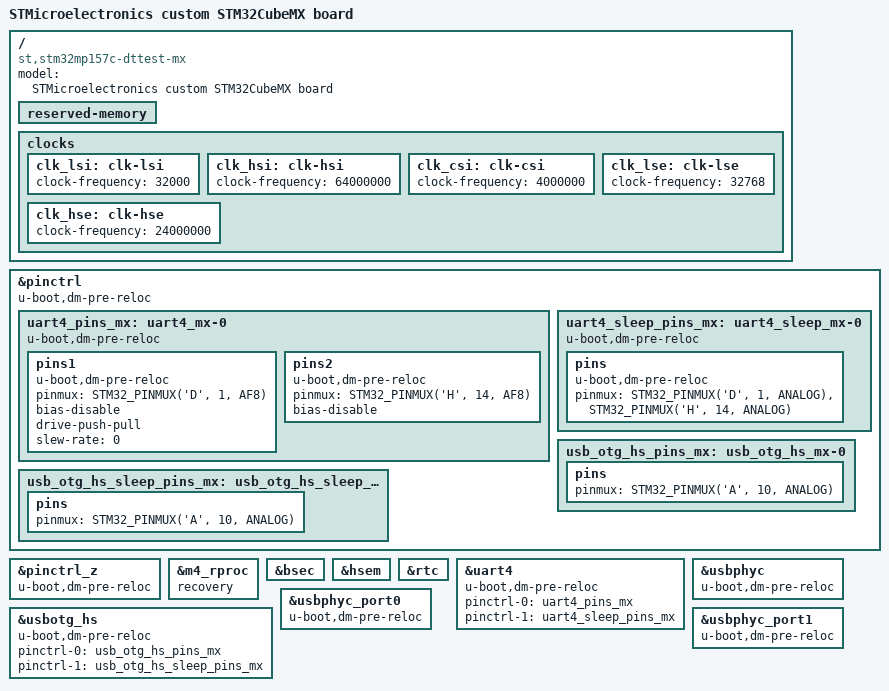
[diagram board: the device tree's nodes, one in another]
/* SPDX-License-Identifier: (GPL-2.0+ OR BSD-3-Clause) */
/*
 * Copyright (C) STMicroelectronics 2020 - All Rights Reserved
 * Author: STM32CubeMX code generation for STMicroelectronics.
 */

/* For more information on Device Tree configuration, please refer to
 * https://wiki.st.com/stm32mpu/wiki/Category:Device_tree_configuration
 */

/dts-v1/;
#include "stm32mp157c.dtsi"
#include "stm32mp157c-m4-srm.dtsi"
#include "stm32mp157caa-pinctrl.dtsi"

/* USER CODE BEGIN includes */
/* USER CODE END includes */

/ {
	model = "STMicroelectronics custom STM32CubeMX board";
	compatible = "st,stm32mp157c-dttest-mx", "st,stm32mp157";

	/* !!! log : Warning - no DDR config found: 'memory' node not generated  !!! */

	/*
	memory@??? {
		reg = < ??? >;
	};
	*/

	reserved-memory {
		#address-cells = <1>;
		#size-cells = <1>;
		ranges;

		/* USER CODE BEGIN reserved-memory */
		/* USER CODE END reserved-memory */

		/* !!! log : Warning - no DDR config found: 'gpu_reserved' node not generated  !!! */

		/*
		gpu_reserved: gpu@??? {
			reg = <??? ???}>;
			no-map;
		};
		*/
	};

	/* USER CODE BEGIN root */
	/* USER CODE END root */

	clocks {
		/* USER CODE BEGIN clocks */
		/* USER CODE END clocks */

		clk_lsi: clk-lsi {
			clock-frequency = <32000>;
		};

		clk_hsi: clk-hsi {
			clock-frequency = <64000000>;
		};

		clk_csi: clk-csi {
			clock-frequency = <4000000>;
		};

		clk_lse: clk-lse {
			clock-frequency = <32768>;
		};

		clk_hse: clk-hse {
			clock-frequency = <24000000>;
		};
	};

}; /*root*/

&pinctrl {
	u-boot,dm-pre-reloc;

	uart4_pins_mx: uart4_mx-0 {
		u-boot,dm-pre-reloc;
		pins1 {
			u-boot,dm-pre-reloc;
			pinmux = <STM32_PINMUX('D', 1, AF8)>; /* UART4_TX */
			bias-disable;
			drive-push-pull;
			slew-rate = <0>;
		};
		pins2 {
			u-boot,dm-pre-reloc;
			pinmux = <STM32_PINMUX('H', 14, AF8)>; /* UART4_RX */
			bias-disable;
		};
	};

	uart4_sleep_pins_mx: uart4_sleep_mx-0 {
		u-boot,dm-pre-reloc;
		pins {
			u-boot,dm-pre-reloc;
			pinmux = <STM32_PINMUX('D', 1, ANALOG)>, /* UART4_TX */
					 <STM32_PINMUX('H', 14, ANALOG)>; /* UART4_RX */
		};
	};

	usb_otg_hs_pins_mx: usb_otg_hs_mx-0 {
		pins {
			pinmux = <STM32_PINMUX('A', 10, ANALOG)>; /* USB_OTG_HS_ID */
		};
	};

	usb_otg_hs_sleep_pins_mx: usb_otg_hs_sleep_mx-0 {
		pins {
			pinmux = <STM32_PINMUX('A', 10, ANALOG)>; /* USB_OTG_HS_ID */
		};
	};

	/* USER CODE BEGIN pinctrl */
	/* USER CODE END pinctrl */
};

&pinctrl_z {
	u-boot,dm-pre-reloc;

	/* USER CODE BEGIN pinctrl_z */
	/* USER CODE END pinctrl_z */
};

&m4_rproc{
	recovery;
	status = "okay";

	/* USER CODE BEGIN m4_rproc */
	/* USER CODE END m4_rproc */
};

&bsec{
	status = "okay";

	/* USER CODE BEGIN bsec */
	/* USER CODE END bsec */
};

&hsem{
	status = "okay";

	/* USER CODE BEGIN hsem */
	/* USER CODE END hsem */
};

&rtc{
	status = "okay";

	/* USER CODE BEGIN rtc */
	/* USER CODE END rtc */
};

&uart4{
	u-boot,dm-pre-reloc;
	pinctrl-names = "default", "sleep";
	pinctrl-0 = <&uart4_pins_mx>;
	pinctrl-1 = <&uart4_sleep_pins_mx>;
	status = "okay";

	/* USER CODE BEGIN uart4 */
	/* USER CODE END uart4 */
};

&usbotg_hs{
	u-boot,dm-pre-reloc;
	pinctrl-names = "default", "sleep";
	pinctrl-0 = <&usb_otg_hs_pins_mx>;
	pinctrl-1 = <&usb_otg_hs_sleep_pins_mx>;
	status = "okay";

	/* USER CODE BEGIN usbotg_hs */
	/* USER CODE END usbotg_hs */
};

&usbphyc{
	u-boot,dm-pre-reloc;
	status = "okay";

	/* USER CODE BEGIN usbphyc */
	/* USER CODE END usbphyc */
};

&usbphyc_port0{
	u-boot,dm-pre-reloc;
	status = "okay";

	/* USER CODE BEGIN usbphyc_port0 */
	/* USER CODE END usbphyc_port0 */
};

&usbphyc_port1{
	u-boot,dm-pre-reloc;
	status = "okay";

	/* USER CODE BEGIN usbphyc_port1 */
	/* USER CODE END usbphyc_port1 */
};

/* USER CODE BEGIN addons */
/* USER CODE END addons */

